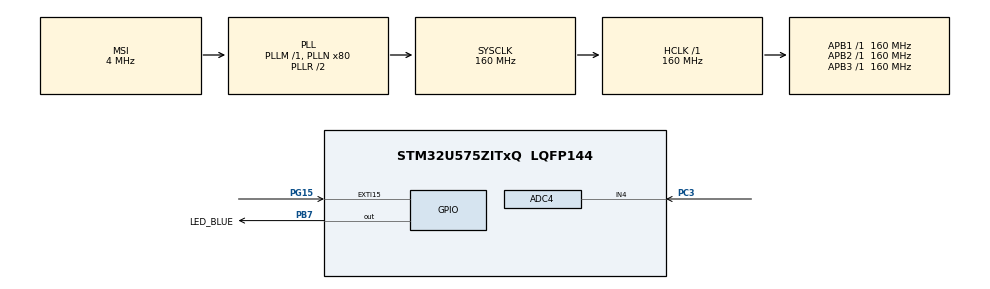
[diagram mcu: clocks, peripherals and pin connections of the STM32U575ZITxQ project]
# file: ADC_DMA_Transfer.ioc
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ADC4.Channel-0\#ChannelRegularConversion=ADC_CHANNEL_4
ADC4.ClockPrescaler=ADC_CLOCK_ASYNC_DIV4
ADC4.ContinuousConvMode=ENABLE
ADC4.DMAContinuousRequests=ENABLE
ADC4.DiscontinuousConvMode=DISABLE
ADC4.EnableRegularConversion=ENABLE
ADC4.NbrOfConversion=1
ADC4.NbrOfConversionFlag=1
ADC4.OffsetNumber-0\#ChannelRegularConversion=ADC_OFFSET_NONE
ADC4.Overrun=ADC_OVR_DATA_OVERWRITTEN
ADC4.OversamplingMode=DISABLE
ADC4.Rank-0\#ChannelRegularConversion=1
ADC4.RankArg-0\#ChannelRegularConversion=ADC4_REGULAR_RANK_1
ADC4.SamplingTime-0\#ChannelRegularConversion=ADC4_SAMPLINGTIME_COMMON_1
ADC4.SamplingTimeCommon1=ADC4_SAMPLETIME_39CYCLES_5
ADC4.SelectedChannel=ADC_CHANNEL_4
ADC4.Sequencer=FULLY_CONFIGURABLE
ADC4.TriggerFrequencyMode=ADC_TRIGGER_FREQ_LOW
CORTEX_M33_NS.userName=CORTEX_M33
GPDMA1.LINKALLOCATEDPORT_GPDMACH10=DMA_LINK_ALLOCATED_PORT1
GPDMA1.LINKEDLISTMODE_GPDMACH10=DMA_LINKEDLIST_CIRCULAR
GPDMA1.TRANSFEREVENTMODE_LL_GPDMACH10=DMA_TCEM_LAST_LL_ITEM_TRANSFER
Linkedlist.MDMA_Channel0.GP_SW.0.BlkHWRequest=DMA_BREQ_SINGLE_BURST
Linkedlist.MDMA_Channel0.GP_SW.0.DataHandling=NONE
Linkedlist.MDMA_Channel0.GP_SW.0.DataSize=0
Linkedlist.MDMA_Channel0.GP_SW.0.DestBurstLength=1
Linkedlist.MDMA_Channel0.GP_SW.0.DestDataWidth=DMA_DEST_DATAWIDTH_WORD
Linkedlist.MDMA_Channel0.GP_SW.0.DestInc=DMA_DINC_INCREMENTED
Linkedlist.MDMA_Channel0.GP_SW.0.Direction=DMA_PERIPH_TO_MEMORY
Linkedlist.MDMA_Channel0.GP_SW.0.DstAddress=0
Linkedlist.MDMA_Channel0.GP_SW.0.Instance=MDMA_Channel0
Linkedlist.MDMA_Channel0.GP_SW.0.LL_MASTERDMA=GPDMA
Linkedlist.MDMA_Channel0.GP_SW.0.LL_NAME=ADCQueue
Linkedlist.MDMA_Channel0.GP_SW.0.LL_TYPE=LINEAR
Linkedlist.MDMA_Channel0.GP_SW.0.NODE_NAME=ADCNode
Linkedlist.MDMA_Channel0.GP_SW.0.Requestforcodegen=GPDMA1_REQUEST_ADC4
Linkedlist.MDMA_Channel0.GP_SW.0.SrcAddress=0
Linkedlist.MDMA_Channel0.GP_SW.0.SrcBurstLength=1
Linkedlist.MDMA_Channel0.GP_SW.0.SrcDataWidth=DMA_SRC_DATAWIDTH_WORD
Linkedlist.MDMA_Channel0.GP_SW.0.SrcInc=DMA_SINC_FIXED
Linkedlist.MDMA_Channel0.GP_SW.0.TransferAllocatedPortSrc=DMA_SRC_ALLOCATED_PORT0
Linkedlist.MDMA_Channel0.GP_SW.0.TransferEventMode=DMA_TCEM_BLOCK_TRANSFER
Linkedlist.MDMA_Channel0.GP_SW.0.TriggerPolarity=DMA_TRIG_POLARITY_MASKED
Linkedlist.MDMA_Channel0.Request0=GP_SW
Linkedlist.MDMA_Channel0.RequestsNb=1
Linkedlist.RequestSet0=MDMA_Channel0
Linkedlist.RequestSetsNb=1
Mcu.Family=STM32U5
Mcu.Name=STM32U575ZITxQ
Mcu.Package=LQFP144
NVIC.GPDMA1_Channel10_IRQn=true\:0\:0\:false\:false\:true\:false\:true\:true\:true
NVIC.PriorityGroup=NVIC_PRIORITYGROUP_4
NVIC.TIM6_IRQn=true\:15\:0\:false\:false\:true\:false\:false\:true\:true
NVIC.TimeBase=TIM6_IRQn
NVIC.TimeBaseIP=TIM6
PB7.GPIO_Label=LED_BLUE
PB7.GPIO_PuPd=GPIO_PULLUP
PB7.GPIO_Speed=GPIO_SPEED_FREQ_HIGH
PB7.Signal=GPIO_Output
PC3.Mode=IN4
PC3.Signal=ADC4_IN4
PG15.Signal=GPXTI15
ProjectManager.HeapSize=0x200
ProjectManager.StackSize=0x400
ProjectManager.TargetToolchain=STM32CubeIDE
RCC.ADCFreq_Value=16000000
RCC.AHBFreq_Value=160000000
RCC.APB1Freq_Value=160000000
RCC.APB1TimFreq_Value=160000000
RCC.APB2Freq_Value=160000000
RCC.APB2TimFreq_Value=160000000
RCC.APB3Freq_Value=160000000
RCC.CortexFreq_Value=160000000
RCC.DACCLockSelectionVirtual=RCC_DAC1CLKSOURCE_LSI
RCC.DACCLockSelectionVirtualString=RCC_DAC1CLKSOURCE_LSI
RCC.EPOD_VALUE=4000000
RCC.HCLKFreq_Value=160000000
RCC.HSE_VALUE=16000000
RCC.HSI48_VALUE=48000000
RCC.HSI_VALUE=16000000
RCC.LSE_VALUE=32768
RCC.LSIDIV_VALUE=32000
RCC.MSI_VALUE=4000000
RCC.PLLN=80
RCC.SYSCLKFreq_VALUE=160000000
RCC.SYSCLKSource=RCC_SYSCLKSOURCE_PLLCLK
RCC.USBFreq_Value=48000000
RCC.VCOOutputFreq_Value=320000000
VP_GPDMA1_VS_GPDMACH10.Mode=LINKEDLIST_GPDMACH10
VP_ICACHE_VS_ICACHE.Mode=DirectMappedCache
VP_LPBAMQUEUE_VS_QUEUE.Mode=QUEUEMODE
VP_LPBAM_VS_SIG1.Mode=SmartRun
VP_LPBAM_VS_SIG4.Mode=LPDMA1
VP_PWR_VS_DBSignals.Mode=DisableDeadBatterySignals
VP_PWR_VS_LPOM.Mode=PowerOptimisation
VP_PWR_VS_SECSignals.Mode=Security/Privilege
VP_SYS_VS_tim6.Mode=TIM6
VP_THREADX_VS_RTOSJjThreadXJjCoreJjDefault.Mode=Core_Default
board=NUCLEO-U575ZI-Q

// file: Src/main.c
/* USER CODE BEGIN Header */
/**
  ******************************************************************************
  * @file           : main.c
  * @brief          : Main program body
  ******************************************************************************
  * @attention
  *
  * Copyright (c) 2021 STMicroelectronics.
  * All rights reserved.
  *
  * This software is licensed under terms that can be found in the LICENSE file
  * in the root directory of this software component.
  * If no LICENSE file comes with this software, it is provided AS-IS.
  *
  ******************************************************************************
  */
/* USER CODE END Header */
#include "main.h"
#include "app_threadx.h"

ADC_HandleTypeDef hadc4;

DMA_HandleTypeDef handle_GPDMA1_Channel10;

void SystemClock_Config(void);
static void SystemPower_Config(void);
static void MX_GPIO_Init(void);
static void MX_GPDMA1_Init(void);
static void MX_ICACHE_Init(void);
static void MX_ADC4_Init(void);

/* USER CODE BEGIN 0 */
#define ADC_CONVERTED_DATA_BUFFER_SIZE   ((uint32_t)  32)   /* Size of array aADCxConvertedData[] */
/* Variable containing ADC conversions data */
uint32_t   aADCxConvertedData[ADC_CONVERTED_DATA_BUFFER_SIZE];
/* USER CODE END 0 */

int main(void)
{
  /* USER CODE BEGIN 1 */
  /* STM32U5xx HAL library initialization:
       - Configure the Flash prefetch
       - Configure the Systick to generate an interrupt each 1 msec
       - Set NVIC Group Priority to 3
       - Low Level Initialization
     */
  /* USER CODE END 1 */

  /* MCU Configuration--------------------------------------------------------*/

  /* Reset of all peripherals, Initializes the Flash interface and the Systick. */
  HAL_Init();

  /* Configure the system clock */
  SystemClock_Config();

  /* Configure the System Power */
  SystemPower_Config();

  /* Initialize all configured peripherals */
  MX_GPIO_Init();
  MX_GPDMA1_Init();
  MX_ICACHE_Init();
  MX_ADC4_Init();
  /* USER CODE BEGIN 2 */
  MX_ADCQueue_Config();
  __HAL_LINKDMA(&hadc4, DMA_Handle, handle_GPDMA1_Channel10);
    HAL_DMAEx_List_SetCircularMode(&ADCQueue);
  if (HAL_DMAEx_List_LinkQ(&handle_GPDMA1_Channel10, &ADCQueue) != HAL_OK)
  {
    Error_Handler();
  }
  if (HAL_ADC_Start_DMA(&hadc4,
                        (uint32_t *)aADCxConvertedData,
                        (ADC_CONVERTED_DATA_BUFFER_SIZE)
                       ) != HAL_OK)
  {
    Error_Handler();
  }
  /* USER CODE END 2 */

  MX_ThreadX_Init();

  /* We should never get here as control is now taken by the scheduler */
  /* Infinite loop */
  while (1)
  {

  }
}

void SystemClock_Config(void)
{
  RCC_OscInitTypeDef RCC_OscInitStruct = {0};
  RCC_ClkInitTypeDef RCC_ClkInitStruct = {0};

  /** Configure the main internal regulator output voltage
  */
  if (HAL_PWREx_ControlVoltageScaling(PWR_REGULATOR_VOLTAGE_SCALE1) != HAL_OK)
  {
    Error_Handler();
  }

  /** Initializes the CPU, AHB and APB buses clocks
  */
  RCC_OscInitStruct.OscillatorType = RCC_OSCILLATORTYPE_HSI|RCC_OSCILLATORTYPE_MSI;
  RCC_OscInitStruct.HSIState = RCC_HSI_ON;
  RCC_OscInitStruct.HSICalibrationValue = RCC_HSICALIBRATION_DEFAULT;
  RCC_OscInitStruct.MSIState = RCC_MSI_ON;
  RCC_OscInitStruct.MSICalibrationValue = RCC_MSICALIBRATION_DEFAULT;
  RCC_OscInitStruct.MSIClockRange = RCC_MSIRANGE_4;
  RCC_OscInitStruct.PLL.PLLState = RCC_PLL_ON;
  RCC_OscInitStruct.PLL.PLLSource = RCC_PLLSOURCE_MSI;
  RCC_OscInitStruct.PLL.PLLMBOOST = RCC_PLLMBOOST_DIV1;
  RCC_OscInitStruct.PLL.PLLM = 1;
  RCC_OscInitStruct.PLL.PLLN = 80;
  RCC_OscInitStruct.PLL.PLLP = 2;
  RCC_OscInitStruct.PLL.PLLQ = 2;
  RCC_OscInitStruct.PLL.PLLR = 2;
  RCC_OscInitStruct.PLL.PLLRGE = RCC_PLLVCIRANGE_0;
  RCC_OscInitStruct.PLL.PLLFRACN = 0;
  if (HAL_RCC_OscConfig(&RCC_OscInitStruct) != HAL_OK)
  {
    Error_Handler();
  }

  /** Initializes the CPU, AHB and APB buses clocks
  */
  RCC_ClkInitStruct.ClockType = RCC_CLOCKTYPE_HCLK|RCC_CLOCKTYPE_SYSCLK
                              |RCC_CLOCKTYPE_PCLK1|RCC_CLOCKTYPE_PCLK2
                              |RCC_CLOCKTYPE_PCLK3;
  RCC_ClkInitStruct.SYSCLKSource = RCC_SYSCLKSOURCE_PLLCLK;
  RCC_ClkInitStruct.AHBCLKDivider = RCC_SYSCLK_DIV1;
  RCC_ClkInitStruct.APB1CLKDivider = RCC_HCLK_DIV1;
  RCC_ClkInitStruct.APB2CLKDivider = RCC_HCLK_DIV1;
  RCC_ClkInitStruct.APB3CLKDivider = RCC_HCLK_DIV1;

  if (HAL_RCC_ClockConfig(&RCC_ClkInitStruct, FLASH_LATENCY_4) != HAL_OK)
  {
    Error_Handler();
  }
}

/**
  * @brief Power Configuration
  * @retval None
  */
static void SystemPower_Config(void)
{
  HAL_PWREx_EnableVddIO2();

  /*
   * Disable the internal Pull-Up in Dead Battery pins of UCPD peripheral
   */
  HAL_PWREx_DisableUCPDDeadBattery();
}

static void MX_ADC4_Init(void)
{

  ADC_ChannelConfTypeDef sConfig = {0};

  /** Common config
  */
  hadc4.Instance = ADC4;
  hadc4.Init.ClockPrescaler = ADC_CLOCK_ASYNC_DIV4;
  hadc4.Init.Resolution = ADC_RESOLUTION_12B;
  hadc4.Init.DataAlign = ADC_DATAALIGN_RIGHT;
  hadc4.Init.ScanConvMode = ADC4_SCAN_DISABLE;
  hadc4.Init.EOCSelection = ADC_EOC_SINGLE_CONV;
  hadc4.Init.LowPowerAutoPowerOff = ADC_LOW_POWER_NONE;
  hadc4.Init.LowPowerAutoWait = DISABLE;
  hadc4.Init.ContinuousConvMode = ENABLE;
  hadc4.Init.NbrOfConversion = 1;
  hadc4.Init.DiscontinuousConvMode = DISABLE;
  hadc4.Init.ExternalTrigConv = ADC_SOFTWARE_START;
  hadc4.Init.ExternalTrigConvEdge = ADC_EXTERNALTRIGCONVEDGE_NONE;
  hadc4.Init.DMAContinuousRequests = ENABLE;
  hadc4.Init.TriggerFrequencyMode = ADC_TRIGGER_FREQ_LOW;
  hadc4.Init.Overrun = ADC_OVR_DATA_OVERWRITTEN;
  hadc4.Init.SamplingTimeCommon1 = ADC4_SAMPLETIME_39CYCLES_5;
  hadc4.Init.SamplingTimeCommon2 = ADC4_SAMPLETIME_1CYCLE_5;
  hadc4.Init.OversamplingMode = DISABLE;
  if (HAL_ADC_Init(&hadc4) != HAL_OK)
  {
    Error_Handler();
  }

  /** Configure Regular Channel
  */
  sConfig.Channel = ADC_CHANNEL_4;
  sConfig.Rank = ADC4_REGULAR_RANK_1;
  sConfig.SamplingTime = ADC4_SAMPLINGTIME_COMMON_1;
  sConfig.OffsetNumber = ADC_OFFSET_NONE;
  sConfig.Offset = 0;
  if (HAL_ADC_ConfigChannel(&hadc4, &sConfig) != HAL_OK)
  {
    Error_Handler();
  }
  /* USER CODE BEGIN ADC4_Init 2 */
  if (HAL_ADCEx_Calibration_Start(&hadc4, ADC_CALIB_OFFSET, ADC_SINGLE_ENDED) != HAL_OK)
  {
    Error_Handler();
  }
  /* USER CODE END ADC4_Init 2 */

}

static void MX_GPDMA1_Init(void)
{

  /* Peripheral clock enable */
  __HAL_RCC_GPDMA1_CLK_ENABLE();

  /* GPDMA1 interrupt Init */
    HAL_NVIC_SetPriority(GPDMA1_Channel10_IRQn, 0, 0);
    HAL_NVIC_EnableIRQ(GPDMA1_Channel10_IRQn);

  handle_GPDMA1_Channel10.Instance = GPDMA1_Channel10;
  handle_GPDMA1_Channel10.InitLinkedList.Priority = DMA_LOW_PRIORITY_LOW_WEIGHT;
  handle_GPDMA1_Channel10.InitLinkedList.LinkStepMode = DMA_LSM_FULL_EXECUTION;
  handle_GPDMA1_Channel10.InitLinkedList.LinkAllocatedPort = DMA_LINK_ALLOCATED_PORT1;
  handle_GPDMA1_Channel10.InitLinkedList.TransferEventMode = DMA_TCEM_LAST_LL_ITEM_TRANSFER;
  handle_GPDMA1_Channel10.InitLinkedList.LinkedListMode = DMA_LINKEDLIST_CIRCULAR;
  if (HAL_DMAEx_List_Init(&handle_GPDMA1_Channel10) != HAL_OK)
  {
    Error_Handler();
  }
  if (HAL_DMA_ConfigChannelAttributes(&handle_GPDMA1_Channel10, DMA_CHANNEL_NPRIV) != HAL_OK)
  {
    Error_Handler();
  }

}

static void MX_ICACHE_Init(void)
{

  /** Enable instruction cache in 1-way (direct mapped cache)
  */
  if (HAL_ICACHE_ConfigAssociativityMode(ICACHE_1WAY) != HAL_OK)
  {
    Error_Handler();
  }
  if (HAL_ICACHE_Enable() != HAL_OK)
  {
    Error_Handler();
  }

}

static void MX_GPIO_Init(void)
{
  GPIO_InitTypeDef GPIO_InitStruct = {0};

  /* GPIO Ports Clock Enable */
  __HAL_RCC_GPIOC_CLK_ENABLE();
  __HAL_RCC_GPIOG_CLK_ENABLE();
  __HAL_RCC_GPIOB_CLK_ENABLE();

  /*Configure GPIO pin Output Level */
  HAL_GPIO_WritePin(LED_BLUE_GPIO_Port, LED_BLUE_Pin, GPIO_PIN_RESET);

  /*Configure GPIO pin : PG15 */
  GPIO_InitStruct.Pin = GPIO_PIN_15;
  GPIO_InitStruct.Mode = GPIO_MODE_IT_RISING;
  GPIO_InitStruct.Pull = GPIO_NOPULL;
  HAL_GPIO_Init(GPIOG, &GPIO_InitStruct);

  /*Configure GPIO pin : LED_BLUE_Pin */
  GPIO_InitStruct.Pin = LED_BLUE_Pin;
  GPIO_InitStruct.Mode = GPIO_MODE_OUTPUT_PP;
  GPIO_InitStruct.Pull = GPIO_PULLUP;
  GPIO_InitStruct.Speed = GPIO_SPEED_FREQ_HIGH;
  HAL_GPIO_Init(LED_BLUE_GPIO_Port, &GPIO_InitStruct);

}

/* USER CODE BEGIN 4 */

/**
  * @brief  Conversion complete callback in non-blocking mode
  * @param  hadc: ADC handle
  * @retval None
  */
void HAL_ADC_ConvHalfCpltCallback(ADC_HandleTypeDef* hadc)
{
  /* Add code to be performed after DMA half complete */
}

/**
  * @brief  Conversion DMA half-transfer callback in non-blocking mode
  * @param  hadc: ADC handle
  * @retval None
  */
void HAL_ADC_ConvCpltCallback(ADC_HandleTypeDef* hadc)
{
  /* Add code to be performed after DMA full complete */
}
/* USER CODE END 4 */

void HAL_TIM_PeriodElapsedCallback(TIM_HandleTypeDef *htim)
{
  if (htim->Instance == TIM6) {
    HAL_IncTick();
  }
}

void Error_Handler(void)
{
  __disable_irq();
  while (1)
  {
  }
}
